# WWDT0_1.0 register map
Vendor: Texas Instruments
Peripheral module from a debugger description file (folder mspm0l11xx_l13xx).
Registers are 32-bit, read-write, no defined reset value unless marked. A register's access mark holds for its fields unless they carry their own. Offsets are as the file gives them; lines under a group give offsets from that group; [hi:lo] are bit positions; {n}, {i} and the like mark numbered series; 'fields as' and 'values as' point back to an identical list; <NAME> marks a mode.

## WWDT0
0x800 WWDT0_GPRCM group
  0x00 WWDT0_PWREN — Power enable
    [0] ENABLE — Enable the power Note: For safety devices the power cannot be disabled once enabled.
      0=DISABLE (Disable Power); 1=ENABLE (Enable Power)
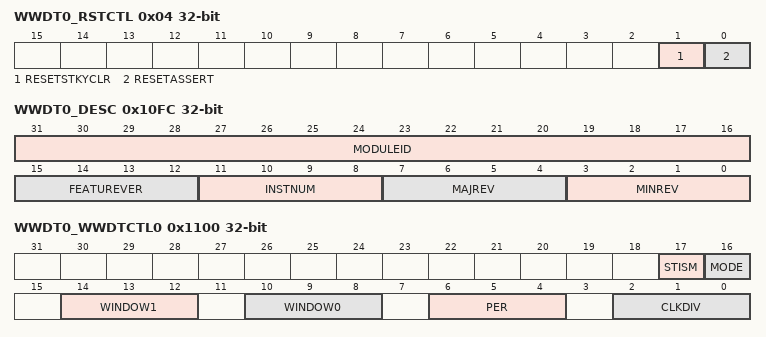
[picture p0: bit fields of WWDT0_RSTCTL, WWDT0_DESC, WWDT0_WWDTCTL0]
  0x04 WWDT0_RSTCTL — Reset Control
    [1] RESETSTKYCLR — Clear [GPRCM.STAT.RESETSTKY]
      0=NOP (Writing 0 has no effect); 1=CLR (Clear reset sticky bit)
    [0] RESETASSERT — Assert reset to the peripheral Note: For safety devices a watchdog reset by software is not possible.
      0=NOP (Writing 0 has no effect); 1=ASSERT (Assert reset)
  0x14 WWDT0_STAT ro — Status Register
    [16] RESETSTKY — This bit indicates, if the peripheral was reset, since this bit was cleared by RESETSTKYCLR in the RSTCTL register
      0=NORES (The peripheral has not been reset since this bit was last cleared by RESETSTKYCLR in the RSTCTL register); 1=RESET (The peripheral was reset since the last bit clear)
0x1018 WWDT0_PDBGCTL — Peripheral Debug Control
  [0] FREE — Free run control
    0=STOP (The peripheral freezes functionality while the Core Halted input is asserted and resumes when it is deasserted.); 1=RUN (The peripheral ignores the state of the Core Halted input)
0x1020 WWDT0_INT_EVENT group
  0x00 WWDT0_IIDX ro — Interrupt index
    [4:0] STAT — Module Interrupt Vector Value. This register provides the highest priority interrupt index. A read clears the corresponding interrupt flag in RIS and MISC.
      0=NO_INTR (No interrupt pending); 1=INTTIM (Interval Timer Interrupt; Interrupt Flag: INTTIM; Interrupt Priority: Highest)
  0x08 WWDT0_IMASK — Interrupt mask
    [0] INTTIM — Interval Timer Interrupt.
      0=CLR (Clear Interrupt Mask); 1=SET (Set Interrupt Mask)
  0x10 WWDT0_RIS — Raw interrupt status
    [0] INTTIM — Interval Timer Interrupt.
      0=CLR (Interrupt did not occur); 1=SET (Interrupt occurred)
  0x18 WWDT0_MIS — Masked interrupt status
    fields as WWDT0_INT_EVENT.WWDT0_RIS
  0x20 WWDT0_ISET — Interrupt set
    [0] INTTIM — Interval Timer Interrupt.
      0=NO_EFFECT (Writing 0 has no effect); 1=SET (Set Interrupt)
  0x28 WWDT0_ICLR — Interrupt clear
    [0] INTTIM — Interval Timer Interrupt.
      0=NO_EFFECT (Writing 0 has no effect); 1=CLR (Clear Interrupt)
0x10E0 WWDT0_EVT_MODE ro — Event Mode
  [1:0] INT0_CFG — Event line mode select for event corresponding to [IPSTANDARD.INT_EVENT][0]
    0=DISABLE (The interrupt or event line is disabled.); 1=SOFTWARE (The interrupt or event line is in software mode. Software must clear the RIS.); 2=HARDWARE (The interrupt or event line is in hardware mode. The hardware (another module) clears automatically the associated RIS flag.)
0x10FC WWDT0_DESC — Module Description
  [31:16] MODULEID — Module identification contains a unique peripheral identification number. The assignments are maintained in a central database for all of the platform modules to ensure uniqueness.
    0=MINIMUM (Smallest value); 0xFFFF=MAXIMUM (Highest possible value)
  [15:12] FEATUREVER — Feature Set for the module *instance*
    0=MINIMUM (Smallest value); 15=MAXIMUM (Highest possible value)
  [11:8] INSTNUM — Instance Number within the device. This will be a parameter to the RTL for modules that can have multiple instances
    values as FEATUREVER
  [7:4] MAJREV — Major rev of the IP
    values as FEATUREVER
  [3:0] MINREV — Minor rev of the IP
    values as FEATUREVER
0x1100 WWDT0_WWDTCTL0 — Window Watchdog Timer Control Register 0
  [17] STISM — Stop In Sleep Mode. The functionality of this bit requires that POLICY.HWCEN = 0. If POLICY.HWCEN = 1 the WWDT resets during sleep and needs re-configuration. Note: This bit has no effect for the global Window Watchdog as Sleep Mode is not supported.
    0=CONT (The WWDT continues to function in Sleep mode.); 1=STOP (The WWDT stops in Sleep mode and resumes where it was stopped after wakeup.)
  [16] MODE — Window Watchdog Timer Mode
    0=WINDOW (Window Watchdog Timer Mode. The WWDT will generate a error signal to the ESM when following conditions occur: - Timer Expiration (Timeout) - Reset WWDT during the active window closed period - Keyword violation); 1=INTERVAL (Interval Timer Mode. The WWDT acts as an interval timer. It generates an interrupt on timeout.)
  [14:12] WINDOW1 — Closed window period in percentage of the timer interval. WWDTCTL1.WINSEL determines the active window setting (WWDTCTL0.WINDOW0 or WWDTCTL0.WINDOW1).
    0=SIZE_0 (0% (No closed Window)); 1=SIZE_12 (12.50% of the total timer period is closed window); 2=SIZE_18 (18.75% of the total timer period is closed window); 3=SIZE_25 (25% of the total timer period is closed window); 4=SIZE_50 (50% of the total timer period is closed window); 5=SIZE_75 (75% of the total timer period is closed window); 6=SIZE_81 (81.25% of the total timer period is closed window); 7=SIZE_87 (87.50% of the total timer period is closed window)
  [10:8] WINDOW0 — Closed window period in percentage of the timer interval. WWDTCTL1.WINSEL determines the active window setting (WWDTCTL0.WINDOW0 or WWDTCTL0.WINDOW1).
    values as WINDOW1
  [6:4] PER — Timer Period of the WWDT. These bits select the total watchdog timer count.
    0=EN_25 (Total timer count is 2^25); 1=EN_21 (Total timer count is 2^21); 2=EN_18 (Total timer count is 2^18); 3=EN_15 (Total timer count is 2^15); 4=EN_12 (Total timer count is 2^12 (default)); 5=EN_10 (Total timer count is 2^10); 6=EN_8 (Total timer count is 2^8); 7=EN_6 (Total timer count is 2^6)
  [2:0] CLKDIV — Module Clock Divider, Divide the clock source by CLKDIV+1. Divider values from /1 to /8 are possible. The clock divider is currently 4 bits. Bit 4 has no effect and should always be written with 0.
    0=MINIMUM (Minimum value); 7=MAXIMUM (Maximum value)
0x1104 WWDT0_WWDTCTL1 — Window Watchdog Timer Control Register 0
  [0] WINSEL — Close Window Select
    0=WIN0 (In window mode field WINDOW0 of WDDTCTL0 defines the closed window size. In interval mode field WINDOW0 defines the timeout interval.); 1=WIN1 (In window mode field WINDOW1 of WDDTCTL0 defines the closed window size. In interval mode field WINDOW1 defines the timeout interval.)
0x1108 WWDT0_WWDTCNTRST — Window Watchdog Timer Counter Reset Register
  [31:0] RESTART — Window Watchdog Timer Counter Restart Writing 00A7h to this register restarts the WWDT Counter. Writing any other value causes an error generation to the ESM. Read as 0.
    0=MINIMUM (Minimum value); 0xFFFFFFFF=MAXIMUM (Maximum value)
0x110C WWDT0_WWDTSTAT ro — Window Watchdog Timer Status Register
  [0] RUN — Watchdog running status flag.
    0=OFF (Watchdog counter stopped.); 1=ON (Watchdog running.)
